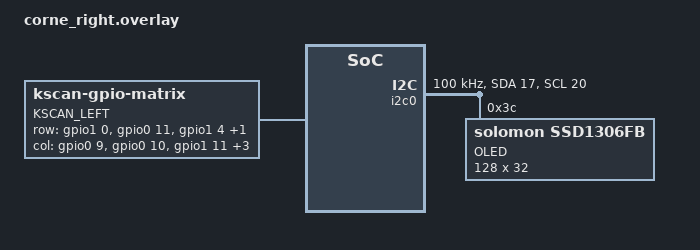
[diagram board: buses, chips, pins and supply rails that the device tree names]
/ {
    chosen { zmk,kscan = &kscan0; };

    kscan0: kscan {
        compatible = "zmk,kscan-gpio-matrix";
        label = "KSCAN_LEFT";

        /* Rows: In row2col, rows are drivers. No pull flags. */
        row-gpios = <&gpio1 0  GPIO_ACTIVE_HIGH>,
                    <&gpio0 11 GPIO_ACTIVE_HIGH>,
                    <&gpio1 4  GPIO_ACTIVE_HIGH>,
                    <&gpio1 6  GPIO_ACTIVE_HIGH>;

        /* Cols: In row2col, columns are listeners. They get the PULL_DOWN flags. */
        col-gpios = <&gpio0 9  (GPIO_ACTIVE_HIGH | GPIO_PULL_DOWN)>,
                    <&gpio0 10 (GPIO_ACTIVE_HIGH | GPIO_PULL_DOWN)>,
                    <&gpio1 11 (GPIO_ACTIVE_HIGH | GPIO_PULL_DOWN)>,
                    <&gpio1 13 (GPIO_ACTIVE_HIGH | GPIO_PULL_DOWN)>,
                    <&gpio1 15 (GPIO_ACTIVE_HIGH | GPIO_PULL_DOWN)>,
                    <&gpio0 2  (GPIO_ACTIVE_HIGH | GPIO_PULL_DOWN)>;

        diode-direction = "row2col"; // Enforced row2col scanning
        debounce-press-ms = <5>;
        debounce-release-ms = <5>;
        wakeup-source;
    };

    matrix_transform {
        compatible = "zmk,matrix-transform";
        columns = <6>;
        rows = <4>;
        map = <0 1 2 3 4 5  6 7 8 9 10 11  12 13 14 15 16 17  18 19 20 21 22 23>;
    };
};

&i2c0 {
    status = "okay";
    sda-pin = <17>;
    scl-pin = <20>;
    clock-frequency = <I2C_BITRATE_STANDARD>;

    oled0: oled@3c {
        compatible = "solomon,ssd1306fb";
        reg = <0x3C>;
        width = <128>;
        height = <32>;
        label = "OLED";
    };
};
